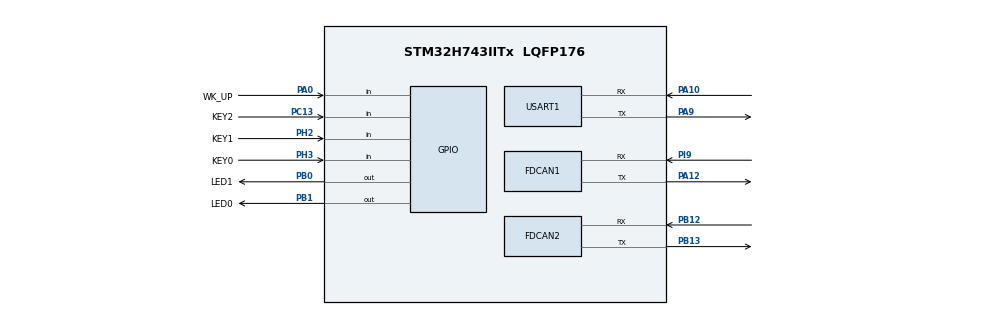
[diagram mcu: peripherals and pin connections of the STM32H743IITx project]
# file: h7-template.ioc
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CORTEX_M7.default_mode_Activation=1
Dma.Request0=USART1_RX
Dma.Request1=USART1_TX
Dma.USART1_RX.0.Direction=DMA_PERIPH_TO_MEMORY
Dma.USART1_RX.0.EventEnable=DISABLE
Dma.USART1_RX.0.FIFOMode=DMA_FIFOMODE_DISABLE
Dma.USART1_RX.0.Instance=DMA1_Stream0
Dma.USART1_RX.0.MemDataAlignment=DMA_MDATAALIGN_BYTE
Dma.USART1_RX.0.MemInc=DMA_MINC_ENABLE
Dma.USART1_RX.0.Mode=DMA_NORMAL
Dma.USART1_RX.0.PeriphDataAlignment=DMA_PDATAALIGN_BYTE
Dma.USART1_RX.0.PeriphInc=DMA_PINC_DISABLE
Dma.USART1_RX.0.Polarity=HAL_DMAMUX_REQ_GEN_RISING
Dma.USART1_RX.0.Priority=DMA_PRIORITY_LOW
Dma.USART1_RX.0.RequestNumber=1
Dma.USART1_RX.0.SignalID=NONE
Dma.USART1_RX.0.SyncEnable=DISABLE
Dma.USART1_RX.0.SyncPolarity=HAL_DMAMUX_SYNC_NO_EVENT
Dma.USART1_RX.0.SyncRequestNumber=1
Dma.USART1_RX.0.SyncSignalID=NONE
Dma.USART1_TX.1.Direction=DMA_MEMORY_TO_PERIPH
Dma.USART1_TX.1.EventEnable=DISABLE
Dma.USART1_TX.1.FIFOMode=DMA_FIFOMODE_DISABLE
Dma.USART1_TX.1.Instance=DMA1_Stream1
Dma.USART1_TX.1.MemDataAlignment=DMA_MDATAALIGN_BYTE
Dma.USART1_TX.1.MemInc=DMA_MINC_ENABLE
Dma.USART1_TX.1.Mode=DMA_NORMAL
Dma.USART1_TX.1.PeriphDataAlignment=DMA_PDATAALIGN_BYTE
Dma.USART1_TX.1.PeriphInc=DMA_PINC_DISABLE
Dma.USART1_TX.1.Polarity=HAL_DMAMUX_REQ_GEN_RISING
Dma.USART1_TX.1.Priority=DMA_PRIORITY_LOW
Dma.USART1_TX.1.RequestNumber=1
Dma.USART1_TX.1.SignalID=NONE
Dma.USART1_TX.1.SyncEnable=DISABLE
Dma.USART1_TX.1.SyncPolarity=HAL_DMAMUX_SYNC_NO_EVENT
Dma.USART1_TX.1.SyncRequestNumber=1
Dma.USART1_TX.1.SyncSignalID=NONE
FDCAN1.CalculateBaudRateNominal=999999
FDCAN1.CalculateTimeBitNominal=1000
FDCAN1.CalculateTimeQuantumNominal=8.333333333333334
FDCAN1.ExtFiltersNbr=2
FDCAN1.NominalPrescaler=1
FDCAN1.NominalSyncJumpWidth=4
FDCAN1.NominalTimeSeg1=89
FDCAN1.NominalTimeSeg2=30
FDCAN1.RxFifo0ElmtsNbr=3
FDCAN1.RxFifo1ElmtsNbr=3
FDCAN1.StdFiltersNbr=2
FDCAN2.AutoRetransmission=ENABLE
FDCAN2.CalculateBaudRateNominal=999999
FDCAN2.CalculateTimeBitNominal=1000
FDCAN2.CalculateTimeQuantumNominal=8.333333333333334
FDCAN2.ExtFiltersNbr=2
FDCAN2.NominalPrescaler=1
FDCAN2.NominalSyncJumpWidth=4
FDCAN2.NominalTimeSeg1=89
FDCAN2.NominalTimeSeg2=30
FDCAN2.ProtocolException=ENABLE
FDCAN2.RxFifo0ElmtsNbr=3
FDCAN2.RxFifo1ElmtsNbr=3
FDCAN2.StdFiltersNbr=2
FDCAN2.TransmitPause=DISABLE
Mcu.Family=STM32H7
Mcu.Name=STM32H743IITx
Mcu.Package=LQFP176
NVIC.DMA1_Stream0_IRQn=true\:0\:0\:false\:false\:true\:false\:true\:true
NVIC.DMA1_Stream1_IRQn=true\:0\:0\:false\:false\:true\:false\:true\:true
NVIC.FDCAN1_IT0_IRQn=true\:5\:0\:true\:false\:true\:true\:true\:true
NVIC.FDCAN1_IT1_IRQn=true\:5\:0\:true\:false\:true\:true\:true\:true
NVIC.FDCAN2_IT0_IRQn=true\:5\:0\:true\:false\:true\:true\:true\:true
NVIC.FDCAN2_IT1_IRQn=true\:5\:0\:true\:false\:true\:true\:true\:true
NVIC.PriorityGroup=NVIC_PRIORITYGROUP_4
NVIC.USART1_IRQn=true\:5\:0\:true\:false\:true\:false\:true\:true
PA0.GPIO_Label=WK_UP
PA0.GPIO_PuPd=GPIO_PULLDOWN
PA0.Signal=GPIO_Input
PA10.Mode=Asynchronous
PA10.Signal=USART1_RX
PA12.Mode=FDCAN_Activate
PA12.Signal=FDCAN1_TX
PA13\ (JTMS/SWDIO).Mode=Trace_Asynchronous_SW
PA13\ (JTMS/SWDIO).Signal=DEBUG_JTMS-SWDIO
PA14\ (JTCK/SWCLK).Mode=Trace_Asynchronous_SW
PA14\ (JTCK/SWCLK).Signal=DEBUG_JTCK-SWCLK
PA9.Mode=Asynchronous
PA9.Signal=USART1_TX
PB0.GPIO_Label=LED1
PB0.GPIO_Speed=GPIO_SPEED_FREQ_HIGH
PB0.Signal=GPIO_Output
PB1.GPIO_Label=LED0
PB1.Signal=GPIO_Output
PB12.Mode=FDCAN_Activate
PB12.Signal=FDCAN2_RX
PB13.Mode=FDCAN_Activate
PB13.Signal=FDCAN2_TX
PB3\ (JTDO/TRACESWO).Mode=Trace_Asynchronous_SW
PB3\ (JTDO/TRACESWO).Signal=DEBUG_JTDO-SWO
PC13.GPIO_Label=KEY2
PC13.GPIO_PuPd=GPIO_PULLUP
PC13.Signal=GPIO_Input
PC14-OSC32_IN\ (OSC32_IN).Mode=LSE-External-Oscillator
PC14-OSC32_IN\ (OSC32_IN).Signal=RCC_OSC32_IN
PC15-OSC32_OUT\ (OSC32_OUT).Mode=LSE-External-Oscillator
PC15-OSC32_OUT\ (OSC32_OUT).Signal=RCC_OSC32_OUT
PH0-OSC_IN\ (PH0).Mode=HSE-External-Oscillator
PH0-OSC_IN\ (PH0).Signal=RCC_OSC_IN
PH1-OSC_OUT\ (PH1).Mode=HSE-External-Oscillator
PH1-OSC_OUT\ (PH1).Signal=RCC_OSC_OUT
PH2.GPIO_Label=KEY1
PH2.GPIO_PuPd=GPIO_PULLUP
PH2.Signal=GPIO_Input
PH3.GPIO_Label=KEY0
PH3.GPIO_PuPd=GPIO_PULLUP
PH3.Signal=GPIO_Input
PI9.Mode=FDCAN_Activate
PI9.Signal=FDCAN1_RX
ProjectManager.HeapSize=0x2000
ProjectManager.StackSize=0x1000
ProjectManager.TargetToolchain=Makefile
RCC.ADCFreq_Value=50390625
RCC.APB1Freq_Value=120000000
RCC.APB2Freq_Value=120000000
RCC.APB3Freq_Value=120000000
RCC.APB4Freq_Value=120000000
RCC.CortexFreq_Value=480000000
RCC.D1PPRE=RCC_APB3_DIV2
RCC.D2PPRE1=RCC_APB1_DIV2
RCC.D2PPRE2=RCC_APB2_DIV2
RCC.D3PPRE=RCC_APB4_DIV2
RCC.DIVM1=5
RCC.DIVN1=192
RCC.DIVQ1=8
RCC.HCLKFreq_Value=240000000
RCC.HPRE=RCC_HCLK_DIV2
RCC.PLL2FRACN=0
RCC.PLL3FRACN=0
RCC.PLLFRACN=0
RCC.PLLSourceVirtual=RCC_PLLSOURCE_HSE
RCC.SYSCLKFreq_VALUE=480000000
RCC.SYSCLKSource=RCC_SYSCLKSOURCE_PLLCLK
RCC.USBFreq_Value=120000000
USART1.VirtualMode-Asynchronous=VM_ASYNC
VP_MEMORYMAP_VS_MEMORYMAP.Mode=CurAppReg
board=custom

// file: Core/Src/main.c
/* USER CODE BEGIN Header */
/**
  ******************************************************************************
  * @file           : main.c
  * @brief          : Main program body
  ******************************************************************************
  * @attention
  *
  * Copyright (c) 2026 STMicroelectronics.
  * All rights reserved.
  *
  * This software is licensed under terms that can be found in the LICENSE file
  * in the root directory of this software component.
  * If no LICENSE file comes with this software, it is provided AS-IS.
  *
  ******************************************************************************
  */
/* USER CODE END Header */
#include "main.h"
#include "dma.h"
#include "fdcan.h"
#include "usart.h"
#include "gpio.h"

/* USER CODE BEGIN Includes */
#include <bsp.h>
/* USER CODE END Includes */

void SystemClock_Config(void);
static void MPU_Config(void);
/* USER CODE BEGIN PFP */
extern void freertos_start(void);
/* USER CODE END PFP */

int main(void)
{

  /* MPU Configuration--------------------------------------------------------*/
  MPU_Config();

  /* MCU Configuration--------------------------------------------------------*/

  /* Reset of all peripherals, Initializes the Flash interface and the Systick. */
  HAL_Init();

  /* Configure the system clock */
  SystemClock_Config();

  /* USER CODE BEGIN SysInit */
  delay_init(480);
  /* USER CODE END SysInit */

  /* Initialize all configured peripherals */
  MX_GPIO_Init();
  MX_DMA_Init();
  MX_FDCAN1_Init();
  MX_FDCAN2_Init();
  MX_USART1_UART_Init();
  /* USER CODE BEGIN 2 */
  bsp_init();
  freertos_start();
  /* USER CODE END 2 */

  /* Infinite loop */
  /* USER CODE BEGIN WHILE */
#if 0
  while (1)
  {
    /* USER CODE END WHILE */

    /* USER CODE BEGIN 3 */
  }
#endif
  /* USER CODE END 3 */
}

void SystemClock_Config(void)
{
  RCC_OscInitTypeDef RCC_OscInitStruct = {0};
  RCC_ClkInitTypeDef RCC_ClkInitStruct = {0};

  /** Supply configuration update enable
  */
  HAL_PWREx_ConfigSupply(PWR_LDO_SUPPLY);

  /** Configure the main internal regulator output voltage
  */
  __HAL_PWR_VOLTAGESCALING_CONFIG(PWR_REGULATOR_VOLTAGE_SCALE0);

  while(!__HAL_PWR_GET_FLAG(PWR_FLAG_VOSRDY)) {}

  /** Initializes the RCC Oscillators according to the specified parameters
  * in the RCC_OscInitTypeDef structure.
  */
  RCC_OscInitStruct.OscillatorType = RCC_OSCILLATORTYPE_HSE;
  RCC_OscInitStruct.HSEState = RCC_HSE_ON;
  RCC_OscInitStruct.PLL.PLLState = RCC_PLL_ON;
  RCC_OscInitStruct.PLL.PLLSource = RCC_PLLSOURCE_HSE;
  RCC_OscInitStruct.PLL.PLLM = 5;
  RCC_OscInitStruct.PLL.PLLN = 192;
  RCC_OscInitStruct.PLL.PLLP = 2;
  RCC_OscInitStruct.PLL.PLLQ = 8;
  RCC_OscInitStruct.PLL.PLLR = 2;
  RCC_OscInitStruct.PLL.PLLRGE = RCC_PLL1VCIRANGE_2;
  RCC_OscInitStruct.PLL.PLLVCOSEL = RCC_PLL1VCOWIDE;
  RCC_OscInitStruct.PLL.PLLFRACN = 0;
  if (HAL_RCC_OscConfig(&RCC_OscInitStruct) != HAL_OK)
  {
    Error_Handler();
  }

  /** Initializes the CPU, AHB and APB buses clocks
  */
  RCC_ClkInitStruct.ClockType = RCC_CLOCKTYPE_HCLK|RCC_CLOCKTYPE_SYSCLK
                              |RCC_CLOCKTYPE_PCLK1|RCC_CLOCKTYPE_PCLK2
                              |RCC_CLOCKTYPE_D3PCLK1|RCC_CLOCKTYPE_D1PCLK1;
  RCC_ClkInitStruct.SYSCLKSource = RCC_SYSCLKSOURCE_PLLCLK;
  RCC_ClkInitStruct.SYSCLKDivider = RCC_SYSCLK_DIV1;
  RCC_ClkInitStruct.AHBCLKDivider = RCC_HCLK_DIV2;
  RCC_ClkInitStruct.APB3CLKDivider = RCC_APB3_DIV2;
  RCC_ClkInitStruct.APB1CLKDivider = RCC_APB1_DIV2;
  RCC_ClkInitStruct.APB2CLKDivider = RCC_APB2_DIV2;
  RCC_ClkInitStruct.APB4CLKDivider = RCC_APB4_DIV2;

  if (HAL_RCC_ClockConfig(&RCC_ClkInitStruct, FLASH_LATENCY_4) != HAL_OK)
  {
    Error_Handler();
  }
}

 /* MPU Configuration */

void MPU_Config(void)
{
  MPU_Region_InitTypeDef MPU_InitStruct = {0};

  /* Disables the MPU */
  HAL_MPU_Disable();

  /** Initializes and configures the Region and the memory to be protected
  */
  MPU_InitStruct.Enable = MPU_REGION_ENABLE;
  MPU_InitStruct.Number = MPU_REGION_NUMBER0;
  MPU_InitStruct.BaseAddress = 0x0;
  MPU_InitStruct.Size = MPU_REGION_SIZE_4GB;
  MPU_InitStruct.SubRegionDisable = 0x87;
  MPU_InitStruct.TypeExtField = MPU_TEX_LEVEL0;
  MPU_InitStruct.AccessPermission = MPU_REGION_NO_ACCESS;
  MPU_InitStruct.DisableExec = MPU_INSTRUCTION_ACCESS_DISABLE;
  MPU_InitStruct.IsShareable = MPU_ACCESS_SHAREABLE;
  MPU_InitStruct.IsCacheable = MPU_ACCESS_NOT_CACHEABLE;
  MPU_InitStruct.IsBufferable = MPU_ACCESS_NOT_BUFFERABLE;

  HAL_MPU_ConfigRegion(&MPU_InitStruct);
  /* Enables the MPU */
  HAL_MPU_Enable(MPU_PRIVILEGED_DEFAULT);

}

void Error_Handler(void)
{
  __disable_irq();
  while (1)
  {
  }
}
